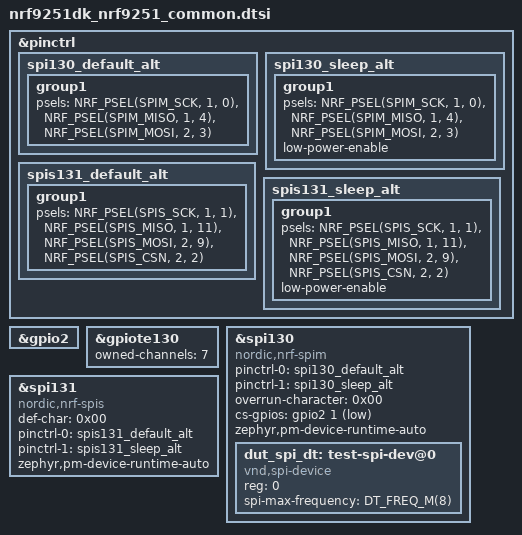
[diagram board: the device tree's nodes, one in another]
/*
 * Copyright (c) 2026 Nordic Semiconductor ASA
 *
 * SPDX-License-Identifier: LicenseRef-Nordic-5-Clause
 */

/* Test requires following loopbacks:
 * SCK:  P1.00 - P1.01
 * MISO: P1.04 - P1.11
 * MOSI: P2.03 - P2.09
 * CS:   P2.01 - P2.02
 */

&pinctrl {
	spi130_default_alt: spi130_default_alt {
		group1 {
			psels = <NRF_PSEL(SPIM_SCK, 1, 0)>,
				<NRF_PSEL(SPIM_MISO, 1, 4)>,
				<NRF_PSEL(SPIM_MOSI, 2, 3)>;
		};
	};

	spi130_sleep_alt: spi130_sleep_alt {
		group1 {
			psels = <NRF_PSEL(SPIM_SCK, 1, 0)>,
				<NRF_PSEL(SPIM_MISO, 1, 4)>,
				<NRF_PSEL(SPIM_MOSI, 2, 3)>;
			low-power-enable;
		};
	};

	spis131_default_alt: spis131_default_alt {
		group1 {
			psels = <NRF_PSEL(SPIS_SCK, 1, 1)>,
				<NRF_PSEL(SPIS_MISO, 1, 11)>,
				<NRF_PSEL(SPIS_MOSI, 2, 9)>,
				<NRF_PSEL(SPIS_CSN, 2, 2)>;
		};
	};

	spis131_sleep_alt: spis131_sleep_alt {
		group1 {
			psels = <NRF_PSEL(SPIS_SCK, 1, 1)>,
				<NRF_PSEL(SPIS_MISO, 1, 11)>,
				<NRF_PSEL(SPIS_MOSI, 2, 9)>,
				<NRF_PSEL(SPIS_CSN, 2, 2)>;
			low-power-enable;
		};
	};
};

&gpio2 {
	status = "okay";
};

&gpiote130 {
	status = "okay";
	owned-channels = <7>;
};

&spi130 {
	compatible = "nordic,nrf-spim";
	status = "okay";
	pinctrl-0 = <&spi130_default_alt>;
	pinctrl-1 = <&spi130_sleep_alt>;
	pinctrl-names = "default", "sleep";
	overrun-character = <0x00>;
	cs-gpios = <&gpio2 1 GPIO_ACTIVE_LOW>;
	zephyr,pm-device-runtime-auto;

	dut_spi_dt: test-spi-dev@0 {
		compatible = "vnd,spi-device";
		reg = <0>;
		spi-max-frequency = <DT_FREQ_M(8)>;
	};
};

dut_spis: &spi131 {
	compatible = "nordic,nrf-spis";
	status = "okay";
	def-char = <0x00>;
	pinctrl-0 = <&spis131_default_alt>;
	pinctrl-1 = <&spis131_sleep_alt>;
	pinctrl-names = "default", "sleep";
	/delete-property/ rx-delay-supported;
	/delete-property/ rx-delay;
	zephyr,pm-device-runtime-auto;
};
